# LKS32MC07x register map
Vendor: Linko Ltd.; Series: LKS32MC07x; File version: 1.0
CPU: CM0 r1p0, little endian, MPU, no FPU, 3 interrupt priority bits
Registers are 32-bit, read-write, reset 0x0 unless marked. A register's access mark holds for its fields unless they carry their own. Offsets are from the block's base; [hi:lo] are bit positions; {n}, {i} and the like mark numbered series; 'fields as' and 'values as' point back to an identical list.

## CMP — CMP registers
Base 0x40010200
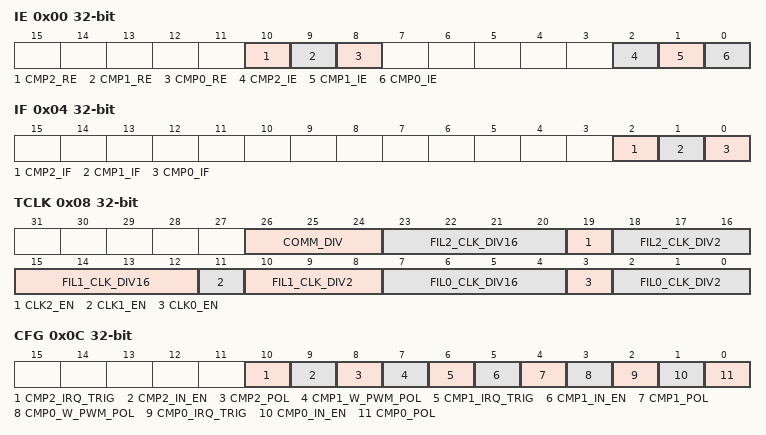
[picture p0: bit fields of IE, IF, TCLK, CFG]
0x00 IE — Comparator interrupt enable
  [10] CMP2_RE — Comparator 2 DMA enable
    0=DISABLED (DMA disabled); 1=ENABLED (DMA enabled)
  [9] CMP1_RE — Comparator 1 DMA enable
    0=DISABLED (DMA disabled); 1=ENABLED (DMA enabled)
  [8] CMP0_RE — Comparator 0 DMA enable
    0=DISABLED (DMA disabled); 1=ENABLED (DMA enabled)
  [2] CMP2_IE — Comparator 2 interrupt enable
    0=DISABLED (irq disabled); 1=ENABLED (irq enabled)
  [1] CMP1_IE — Comparator 1 interrupt enable
    0=DISABLED (irq disabled); 1=ENABLED (irq enabled)
  [0] CMP0_IE — Comparator 0 interrupt enable
    0=DISABLED (irq disabled); 1=ENABLED (irq enabled)
0x04 IF — Comparator interrupt flag
  [2] CMP2_IF — Comparator 2 interrupt flag, write to clear
  [1] CMP1_IF — Comparator 1 interrupt flag, write to clear
  [0] CMP0_IF — Comparator 0 interrupt flag, write to clear
0x08 TCLK — Comparator clock control
  [26:24] COMM_DIV — Common filter clock division factor
  [23:20] FIL2_CLK_DIV16 — Comparator filter clock divided by 1~16
  [19] CLK2_EN — filter clock enable
  [18:16] FIL2_CLK_DIV2 — Comparator filter clock divided by 1/2/4/8/16/32/64/128
    0=1DIV (no division); 1=2DIV (1/2 division); 2=4DIV (1/4 division); 3=8DIV (1/8 division); 4=16DIV (1/16 division); 5=32DIV (1/32 division); 6=64DIV (1/64 division); 7=128DIV (1/128 division)
  [15:12] FIL1_CLK_DIV16 — Comparator filter clock divided by 1~16
  [11] CLK1_EN — filter clock enable
  [10:8] FIL1_CLK_DIV2 — Comparator filter clock divided by 1/2/4/8/16/32/64/128
    values as FIL2_CLK_DIV2
  [7:4] FIL0_CLK_DIV16 — Comparator filter clock divided by 1~16
  [3] CLK0_EN — filter clock enable
  [2:0] FIL0_CLK_DIV2 — Comparator filter clock divided by 1/2/4/8/16/32/64/128
    values as FIL2_CLK_DIV2
0x0C CFG — Comparator configuration
  [10] CMP2_IRQ_TRIG — Comparator 2 irq trigger mechanism
    0=LEVEL_TRIG (Level trigger); 1=EDGE_TRIG (Edge trigger)
  [9] CMP2_IN_EN — Comparator 2 input enable
  [8] CMP2_POL — Comparator 2 polarity
    0=HIGH (high level effective); 1=LOW (low level effective)
  [7] CMP1_W_PWM_POL — PWM signal polarity when used as Comparator 1 opening window contorl signal
  [6] CMP1_IRQ_TRIG — Comparator 1 irq trigger mechanism
    0=LEVEL_TRIG (Level trigger); 1=EDGE_TRIG (Edge trigger)
  [5] CMP1_IN_EN — Comparator 1 input enable
  [4] CMP1_POL — Comparator 1 polarity
    0=HIGH (high level effective); 1=LOW (low level effective)
  [3] CMP0_W_PWM_POL — PWM signal polarity when used as Comparator 0 opening window contorl signal
  [2] CMP0_IRQ_TRIG — Comparator 0 irq trigger mechanism
    0=LEVEL_TRIG (Level trigger); 1=EDGE_TRIG (Edge trigger)
  [1] CMP0_IN_EN — Comparator 0 input enable
  [0] CMP0_POL — Comparator 0 polarity
    0=HIGH (high level effective); 1=LOW (low level effective)
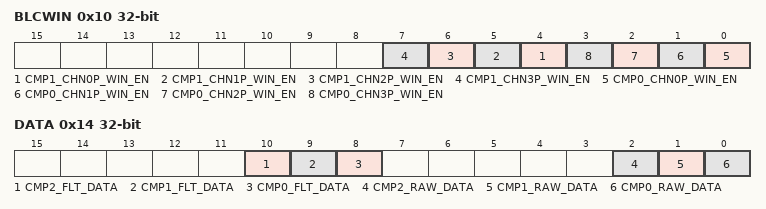
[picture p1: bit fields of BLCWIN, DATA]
0x10 BLCWIN — Comparator black window control
  [n+4] CMP1_CHN{n}P_WIN_EN (n=0..3) — Comparator 1 black window controled by CHN{n}P enable
  [n] CMP0_CHN{n}P_WIN_EN (n=0..3) — Comparator 0 black window controled by CHN{n}P enable
0x14 DATA — Comparator Output Data
  [10] CMP2_FLT_DATA ro — Comparator 2 output after filter
  [9] CMP1_FLT_DATA ro — Comparator 1 output after filter
  [8] CMP0_FLT_DATA ro — Comparator 0 output after filter
  [2] CMP2_RAW_DATA ro — Comparator 2 output
  [1] CMP1_RAW_DATA ro — Comparator 1 output
  [0] CMP0_RAW_DATA ro — Comparator 0 output

## HALL0 — HALL0 registers
Base 0x40010300
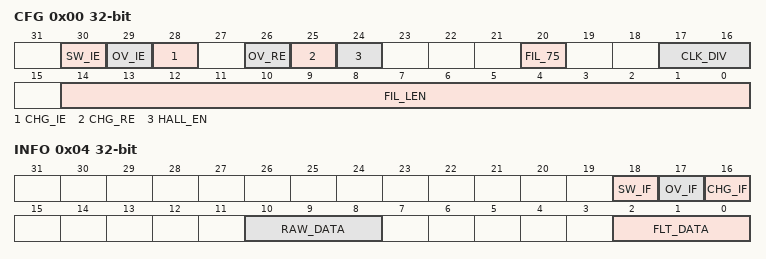
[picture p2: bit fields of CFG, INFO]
0x00 CFG — Hall Configuration Register
  [30] SW_IE — Software to trigger hall irq enable
    0=DISABLED (software trigger interrupt disable); 1=ENABLED (software trigger interrupt enable)
  [29] OV_IE — overflow counter interrupt enable
    0=DISABLED (overflow counter interrupt disable); 1=ENABLED (overflow counter interrupt enable)
  [28] CHG_IE — hall signal change interrupt enable
    0=DISABLED (hall signal change interrupt disable); 1=ENABLED (hall signal change interrupt enable)
  [26] OV_RE — overflow counter DMA request enable
    0=DISABLED (overflow counter DMA request disable); 1=ENABLED (overflow counter DMA request enable)
  [25] CHG_RE — hall signal change DMA request enable
    0=DISABLED (hall signal change DMA request disable); 1=ENABLED (hall signal change DMA request enable)
  [24] HALL_EN — hall enable
    0=DISABLED (hall module disable); 1=ENABLED (hall module enable)
  [20] FIL_75 — hall signal first filter:7_5 filter control bit
    0=DISABLED (hall signal 7_5 filter disable); 1=ENABLED (hall signal 7_5 filter enable)
  [17:16] CLK_DIV — hall clock frequency divider
    0=DVI1 (Divide 1); 1=DIV2 (Divide 2); 2=DIV4 (Divide 4); 3=DIV8 (Divide 8)
  [14:0] FIL_LEN — hall signal second filter:filter length control bits. Filter length from 1 to 32768
0x04 INFO — Hall Information register
  [18] SW_IF wo — software to trigger hall irq
  [17] OV_IF — overflow counter event
    0=NOTSET (read 0 means overflow counter event not happened, write 0 is useless); 1=CLEAR (read 1 means overflow counter event happened, write 1 to clear)
  [16] CHG_IF — hall signal change event
    0=NOTSET (read 0 means hall signal change event not happened, write 0 is useless); 1=CLEAR (read 1 means hall signal change event happened, write 1 to clear)
  [10:8] RAW_DATA ro — hall signal data without filtered
  [2:0] FLT_DATA ro — hall signal data with filtered
0x08 WIDTH ro — Hall Width Register
  [23:0] CAP_CNT — hall signal change event happened,captured hall counter value by hardware
0x0C TH — Hall Threshold Register
  [23:0] TH — overflow event target value
0x10 CNT — Hall Counter Register
  [23:0] CNT — hall counter value
